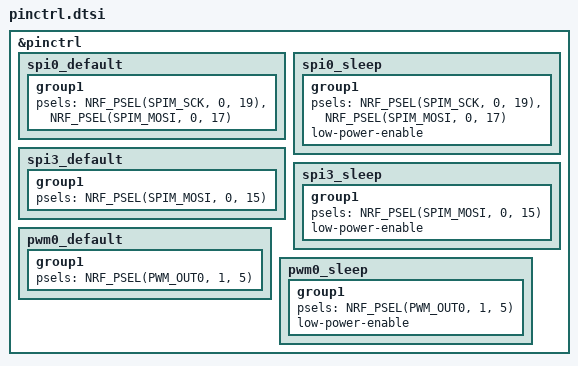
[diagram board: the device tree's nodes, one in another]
/*
 * Copyright (c) 2024 The ZMK Contributors
 * SPDX-License-Identifier: MIT
 */

&pinctrl {
    spi0_default: spi0_default {
        group1 {
            psels = <NRF_PSEL(SPIM_SCK, 0, 19)>,
                <NRF_PSEL(SPIM_MOSI, 0, 17)>;
        };
    };

    spi0_sleep: spi0_sleep {
        group1 {
            psels = <NRF_PSEL(SPIM_SCK, 0, 19)>,
                <NRF_PSEL(SPIM_MOSI, 0, 17)>;
            low-power-enable;
        };
    };
    spi3_default: spi3_default {
        group1 {
            psels = <NRF_PSEL(SPIM_MOSI, 0, 15)>;
        };
    };

    spi3_sleep: spi3_sleep {
        group1 {
            psels = <NRF_PSEL(SPIM_MOSI, 0, 15)>;
            low-power-enable;
        };
    };
    pwm0_default: pwm0_default {
        group1 {
            psels = <NRF_PSEL(PWM_OUT0, 1, 5)>;
        };
    };
    pwm0_sleep: pwm0_sleep {
        group1 {
            psels = <NRF_PSEL(PWM_OUT0, 1, 5)>;
            low-power-enable;
        };
    };
};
